# ESP32-H21 register map
Vendor: ESPRESSIF SYSTEMS (SHANGHAI) CO., LTD.; Series: ESP32 H-Series; File version: 1
CPU: RV32IMAC r0p0, little endian, no MPU, no FPU, 0 interrupt priority bits
Address unit: 32 bits
Registers are 32-bit, read-write, reset 0x0 unless marked. A register's access mark holds for its fields unless they carry their own. Offsets are from the block's base; [hi:lo] are bit positions; lines under a group give offsets from that group; {n}, {i} and the like mark numbered series.

## LP_APM — Low-power Access Permission Management Controller
Base 0x600B3800
Same registers: LP_APM0 0x60099800
0x00 REGION_FILTER_EN reset 0x1 — Region filter enable register
  [3:0] REGION_FILTER_EN — Region filter enable
{0x4+0xC*i} REGION{i} (i=0..3) group — Cluster REGION{i}, containing REGION*_ADDR_START, REGION*_ADDR_END, REGION*_PMS_ATTR
  0x00 ADDR_START — Region address register
    [31:0] ADDR_START — Start address of region0
  0x04 ADDR_END reset 0xFFFFFFFF — Region address register
    [31:0] ADDR_END — End address of region0
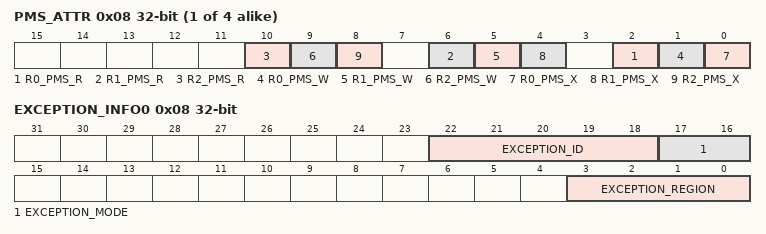
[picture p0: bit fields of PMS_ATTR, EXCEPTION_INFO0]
  0x08 PMS_ATTR — Region access authority attribute register
    [4n+2] R{n}_PMS_R (n=0..2) — Region read authority in REE_MODE{n}
    [4n+1] R{n}_PMS_W (n=0..2) — Region write authority in REE_MODE{n}
    [4n] R{n}_PMS_X (n=0..2) — Region execute authority in REE_MODE{n}
0xC4 FUNC_CTRL reset 0x1 — PMS function control register
  [n] M{n}_PMS_FUNC_EN (n=0..0) — PMS M{n} function enable
{0xC8+0x10*i} M{i} (i=0..0) group — Cluster M{i}, containing M?_STATUS, M?_STATUS_CLR, M?_EXCEPTION_INFO0, M?_EXCEPTION_INFO1
  0x00 STATUS ro — M0 status register
    [1:0] EXCEPTION_STATUS
  0x04 STATUS_CLR wo — M0 status clear register
    [0] REGION_STATUS_CLR — Clear exception status
  0x08 EXCEPTION_INFO0 ro — M0 exception_info0 register
    [22:18] EXCEPTION_ID — Exception id information
    [17:16] EXCEPTION_MODE
    [3:0] EXCEPTION_REGION
  0x0C EXCEPTION_INFO1 ro — M0 exception_info1 register
    [31:0] EXCEPTION_ADDR
0xD8 INT_EN — APM interrupt enable register
  [n] M{n}_APM (n=0..0) — APM M{n} interrupt enable
0xDC CLOCK_GATE reset 0x1 — clock gating register
  [0] CLK_EN — reg_clk_en
0x7FC DATE — Version register

## MODEM_SYSCON
Base 0x600A5400
0x00 TEST_CONF
  [0] CLK_EN
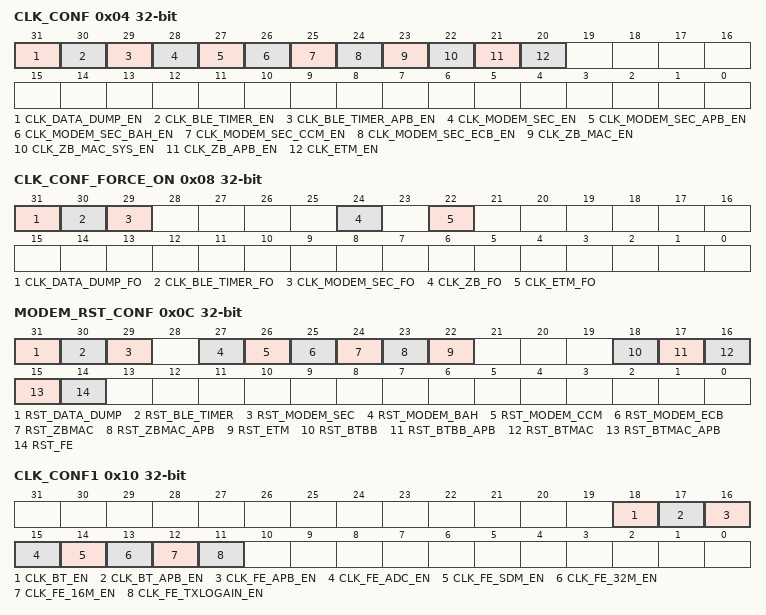
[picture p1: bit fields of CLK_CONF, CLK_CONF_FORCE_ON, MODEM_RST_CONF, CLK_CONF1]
0x04 CLK_CONF
  [31] CLK_DATA_DUMP_EN, [30] CLK_BLE_TIMER_EN, [29] CLK_BLE_TIMER_APB_EN, [28] CLK_MODEM_SEC_EN, [27] CLK_MODEM_SEC_APB_EN, [26] CLK_MODEM_SEC_BAH_EN, [25] CLK_MODEM_SEC_CCM_EN, [24] CLK_MODEM_SEC_ECB_EN, [23] CLK_ZB_MAC_EN, [22] CLK_ZB_MAC_SYS_EN, [21] CLK_ZB_APB_EN, [20] CLK_ETM_EN
0x08 CLK_CONF_FORCE_ON
  [31] CLK_DATA_DUMP_FO, [30] CLK_BLE_TIMER_FO, [29] CLK_MODEM_SEC_FO, [24] CLK_ZB_FO, [22] CLK_ETM_FO
0x0C MODEM_RST_CONF
  [31] RST_DATA_DUMP, [30] RST_BLE_TIMER, [29] RST_MODEM_SEC, [27] RST_MODEM_BAH, [26] RST_MODEM_CCM, [25] RST_MODEM_ECB, [24] RST_ZBMAC, [23] RST_ZBMAC_APB, [22] RST_ETM, [18] RST_BTBB, [17] RST_BTBB_APB, [16] RST_BTMAC, [15] RST_BTMAC_APB, [14] RST_FE
0x10 CLK_CONF1
  [18] CLK_BT_EN, [17] CLK_BT_APB_EN, [16] CLK_FE_APB_EN, [15] CLK_FE_ADC_EN, [14] CLK_FE_SDM_EN, [13] CLK_FE_32M_EN, [12] CLK_FE_16M_EN, [11] CLK_FE_TXLOGAIN_EN
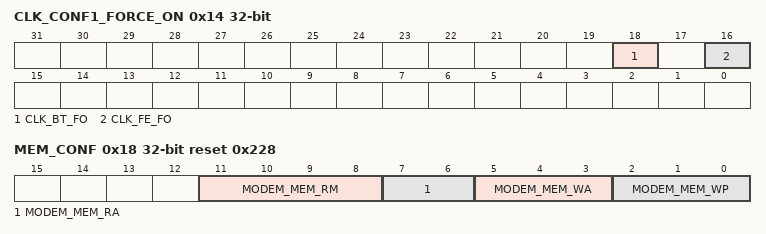
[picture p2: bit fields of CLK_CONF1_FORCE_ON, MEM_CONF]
0x14 CLK_CONF1_FORCE_ON
  [18] CLK_BT_FO, [16] CLK_FE_FO
0x18 MEM_CONF reset 0x228
  [11:8] MODEM_MEM_RM, [7:6] MODEM_MEM_RA, [5:3] MODEM_MEM_WA, [2:0] MODEM_MEM_WP
0x1C DATE

## MODEM_LPCON
Base 0x600AD000
0x00 TEST_CONF
  [0] CLK_EN
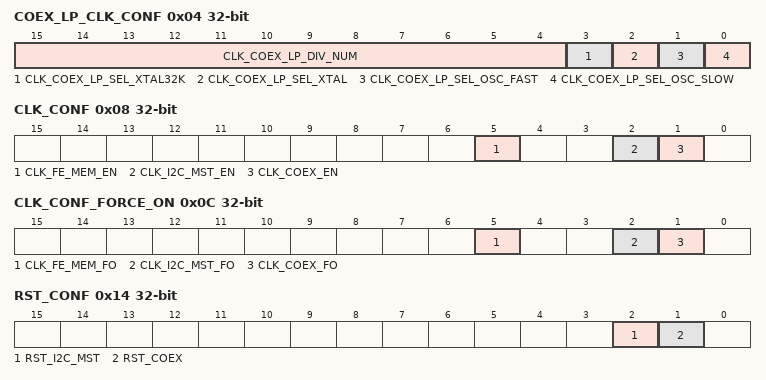
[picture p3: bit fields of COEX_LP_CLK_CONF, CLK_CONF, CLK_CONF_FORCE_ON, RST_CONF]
0x04 COEX_LP_CLK_CONF
  [15:4] CLK_COEX_LP_DIV_NUM, [3] CLK_COEX_LP_SEL_XTAL32K, [2] CLK_COEX_LP_SEL_XTAL, [1] CLK_COEX_LP_SEL_OSC_FAST, [0] CLK_COEX_LP_SEL_OSC_SLOW
0x08 CLK_CONF
  [5] CLK_FE_MEM_EN, [2] CLK_I2C_MST_EN, [1] CLK_COEX_EN
0x0C CLK_CONF_FORCE_ON
  [5] CLK_FE_MEM_FO, [2] CLK_I2C_MST_FO, [1] CLK_COEX_FO
0x10 TICK_CONF ro
  [31:6] PWR_TICK_TARGET
0x14 RST_CONF wo
  [2] RST_I2C_MST, [1] RST_COEX
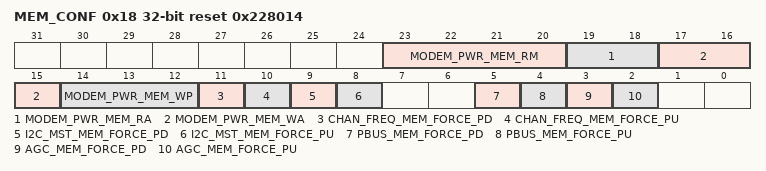
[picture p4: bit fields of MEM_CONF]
0x18 MEM_CONF reset 0x228014
  [23:20] MODEM_PWR_MEM_RM, [19:18] MODEM_PWR_MEM_RA, [17:15] MODEM_PWR_MEM_WA, [14:12] MODEM_PWR_MEM_WP, [11] CHAN_FREQ_MEM_FORCE_PD, [10] CHAN_FREQ_MEM_FORCE_PU, [9] I2C_MST_MEM_FORCE_PD, [8] I2C_MST_MEM_FORCE_PU, [5] PBUS_MEM_FORCE_PD, [4] PBUS_MEM_FORCE_PU, [3] AGC_MEM_FORCE_PD, [2] AGC_MEM_FORCE_PU
0x1C DATE
